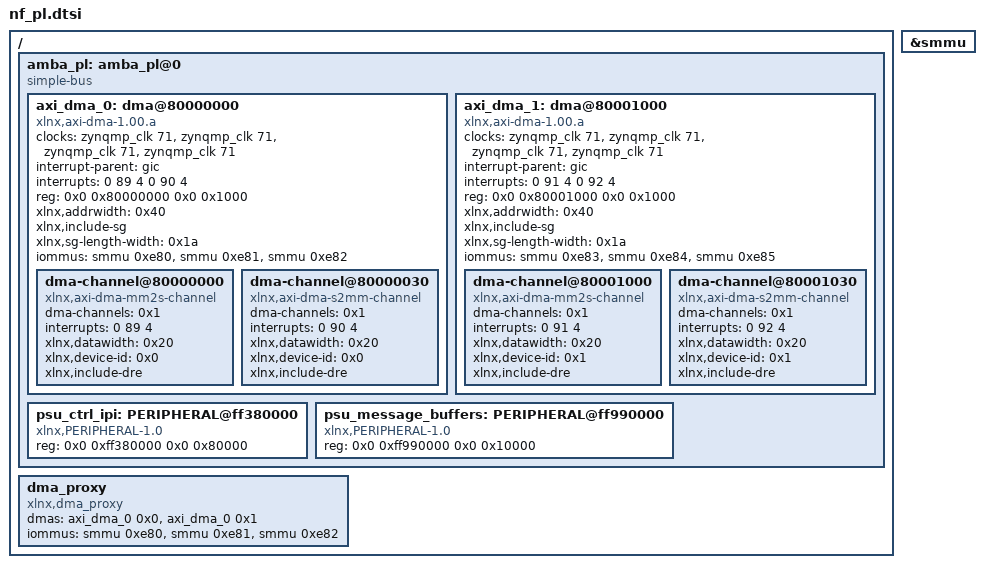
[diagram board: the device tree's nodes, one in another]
/*
 * CAUTION: This file is automatically generated by Xilinx.
 * Version: XSCT 2019.1
 * Today is: Fri Jun 11 15:12:42 2021
 */


/ {
	amba_pl: amba_pl@0 {
		#address-cells = <2>;
		#size-cells = <2>;
		compatible = "simple-bus";
		ranges ;
		axi_dma_0: dma@80000000 {
			#dma-cells = <1>;
			clock-names = "s_axi_lite_aclk", "m_axi_sg_aclk", "m_axi_mm2s_aclk", "m_axi_s2mm_aclk";
			clocks = <&zynqmp_clk 71>, <&zynqmp_clk 71>, <&zynqmp_clk 71>, <&zynqmp_clk 71>;
			compatible = "xlnx,axi-dma-1.00.a";
			interrupt-names = "mm2s_introut", "s2mm_introut";
			interrupt-parent = <&gic>;
			interrupts = <0 89 4 0 90 4>;
			reg = <0x0 0x80000000 0x0 0x1000>;
			xlnx,addrwidth = <0x40>;
			xlnx,include-sg ;
			xlnx,sg-length-width = <0x1a>;
			dma-channel@80000000 {
				compatible = "xlnx,axi-dma-mm2s-channel";
				dma-channels = <0x1>;
				interrupts = <0 89 4>;
				xlnx,datawidth = <0x20>;
				xlnx,device-id = <0x0>;
				xlnx,include-dre ;
			};
			dma-channel@80000030 {
				compatible = "xlnx,axi-dma-s2mm-channel";
				dma-channels = <0x1>;
				interrupts = <0 90 4>;
				xlnx,datawidth = <0x20>;
				xlnx,device-id = <0x0>;
				xlnx,include-dre ;
			};
		};
		axi_dma_1: dma@80001000 {
			#dma-cells = <1>;
			clock-names = "s_axi_lite_aclk", "m_axi_sg_aclk", "m_axi_mm2s_aclk", "m_axi_s2mm_aclk";
			clocks = <&zynqmp_clk 71>, <&zynqmp_clk 71>, <&zynqmp_clk 71>, <&zynqmp_clk 71>;
			compatible = "xlnx,axi-dma-1.00.a";
			interrupt-names = "mm2s_introut", "s2mm_introut";
			interrupt-parent = <&gic>;
			interrupts = <0 91 4 0 92 4>;
			reg = <0x0 0x80001000 0x0 0x1000>;
			xlnx,addrwidth = <0x40>;
			xlnx,include-sg ;
			xlnx,sg-length-width = <0x1a>;
			dma-channel@80001000 {
				compatible = "xlnx,axi-dma-mm2s-channel";
				dma-channels = <0x1>;
				interrupts = <0 91 4>;
				xlnx,datawidth = <0x20>;
				xlnx,device-id = <0x1>;
				xlnx,include-dre ;
			};
			dma-channel@80001030 {
				compatible = "xlnx,axi-dma-s2mm-channel";
				dma-channels = <0x1>;
				interrupts = <0 92 4>;
				xlnx,datawidth = <0x20>;
				xlnx,device-id = <0x1>;
				xlnx,include-dre ;
			};
		};
		psu_ctrl_ipi: PERIPHERAL@ff380000 {
			/* This is a place holder node for a custom IP, user may need to update the entries */
			compatible = "xlnx,PERIPHERAL-1.0";
			reg = <0x0 0xff380000 0x0 0x80000>;
		};
		psu_message_buffers: PERIPHERAL@ff990000 {
			/* This is a place holder node for a custom IP, user may need to update the entries */
			compatible = "xlnx,PERIPHERAL-1.0";
			reg = <0x0 0xff990000 0x0 0x10000>;
		};
	};
	
	 dma_proxy {
                compatible = "xlnx,dma_proxy";
                dmas = <&axi_dma_0 0x0 &axi_dma_0 0x1>;
                dma-names = "dma_proxy_tx", "dma_proxy_rx";
                iommus = <&smmu 0xe80 &smmu 0xe81 &smmu 0xe82>;
        };

};

&smmu {
    status = "okay";
};

&axi_dma_0 {
   iommus = <&smmu 0xe80 &smmu 0xe81 &smmu 0xe82>;
 };

&axi_dma_1 {
   iommus = <&smmu 0xe83 &smmu 0xe84 &smmu 0xe85>;
 };

